# STM32H523 register map
File version: 1.3
CPU: CM33 r0p0, little endian, MPU, FPU, 4 interrupt priority bits
Registers are 32-bit, read-write, reset 0x0 unless marked. A register's access mark holds for its fields unless they carry their own. Offsets are from the block's base; [hi:lo] are bit positions; {n}, {i} and the like mark numbered series.

## TAMP — TAMP register block
Base 0x44007C00
Same registers: TAMP_S 0x54007C00
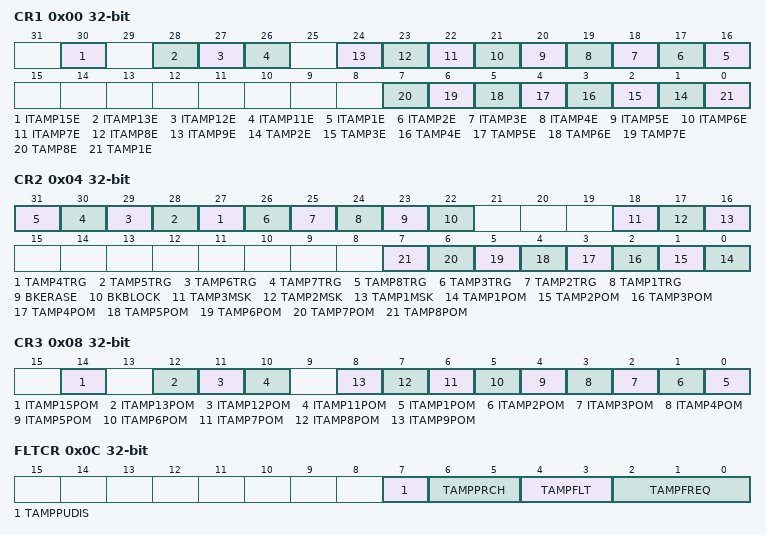
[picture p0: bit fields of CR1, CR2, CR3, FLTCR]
0x00 CR1 — TAMP control register 1
  [30] ITAMP15E — Internal tamper 15 enable
  [28] ITAMP13E — Internal tamper 13 enable
  [27] ITAMP12E — Internal tamper 12 enable
  [26] ITAMP11E — Internal tamper 11 enable
  [n+15] ITAMP{n}E (n=1..9) — Internal tamper {n} enable
  [n-1] TAMP{n}E (n=2..8) — Tamper detection on TAMP_IN{n} enableless thansup>(1)less than/sup>
  [0] TAMP1E — Tamper detection on TAMP_IN1 enable
0x04 CR2 — TAMP control register 2
  [n+23] TAMP{n}TRG (n=4..8) — Active level for tamper {n} input (active mode disabled)
  [26] TAMP3TRG — Active level for tamper 3 input
  [25] TAMP2TRG — Active level for tamper 2 input
  [24] TAMP1TRG — Active level for tamper 1 input
  [23] BKERASE wo — Backup registers and device secretsless thansup>(1)less than/sup> erase
  [22] BKBLOCK — Backup registers and device secretsless thansup>(1)less than/sup> access blocked
  [18] TAMP3MSK — Tamper 3 mask
  [17] TAMP2MSK — Tamper 2 mask
  [16] TAMP1MSK — Tamper 1 mask
  [n-1] TAMP{n}POM (n=1..8) — Tamper {n} potential mode
0x08 CR3 — TAMP control register 3
  [14] ITAMP15POM — Internal tamper 15 potential mode
  [12] ITAMP13POM — Internal tamper 13 potential mode
  [11] ITAMP12POM — Internal tamper 12 potential mode
  [10] ITAMP11POM — Internal tamper 11 potential mode
  [n-1] ITAMP{n}POM (n=1..9) — Internal tamper {n} potential mode
0x0C FLTCR — TAMP filter control register
  [7] TAMPPUDIS — TAMP_INx pull-up disable
  [6:5] TAMPPRCH — TAMP_INx precharge duration
  [4:3] TAMPFLT — TAMP_INx filter count
  [2:0] TAMPFREQ — Tamper sampling frequency
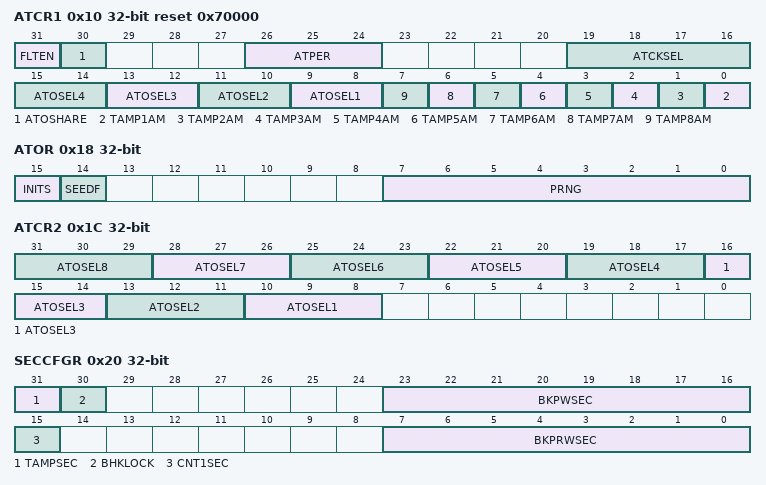
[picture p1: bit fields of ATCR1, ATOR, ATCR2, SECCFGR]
0x10 ATCR1 reset 0x70000 — TAMP active tamper control register 1
  [31] FLTEN — Active tamper filter enable
  [30] ATOSHARE — Active tamper output sharing
  [26:24] ATPER — Active tamper output change period
  [19:16] ATCKSEL — Active tamper RTC asynchronous prescaler clock selection
  [2n+7:2n+6] ATOSEL{n} (n=1..4) — Active tamper shared output {n} selection
  [n-1] TAMP{n}AM (n=1..8) — Tamper {n} active mode
0x14 ATSEEDR wo — TAMP active tamper seed register
  [31:0] SEED — Pseudo-random generator seed value
0x18 ATOR ro — TAMP active tamper output register
  [15] INITS — Active tamper initialization status
  [14] SEEDF — Seed running flag
  [7:0] PRNG — Pseudo-random generator value
0x1C ATCR2 — TAMP active tamper control register 2
  [3n+7:3n+5] ATOSEL{n} (n=1..8) — Active tamper shared output {n} selection
0x20 SECCFGR — TAMP secure configuration register
  [31] TAMPSEC — Tamper protection (excluding monotonic counters and backup registers)
  [30] BHKLOCK — Boot hardware key lock
  [23:16] BKPWSEC — Backup registers write protection offset
  [15] CNT1SEC — Monotonic counter 1 secure protection
  [7:0] BKPRWSEC — Backup registers read/write protection offset
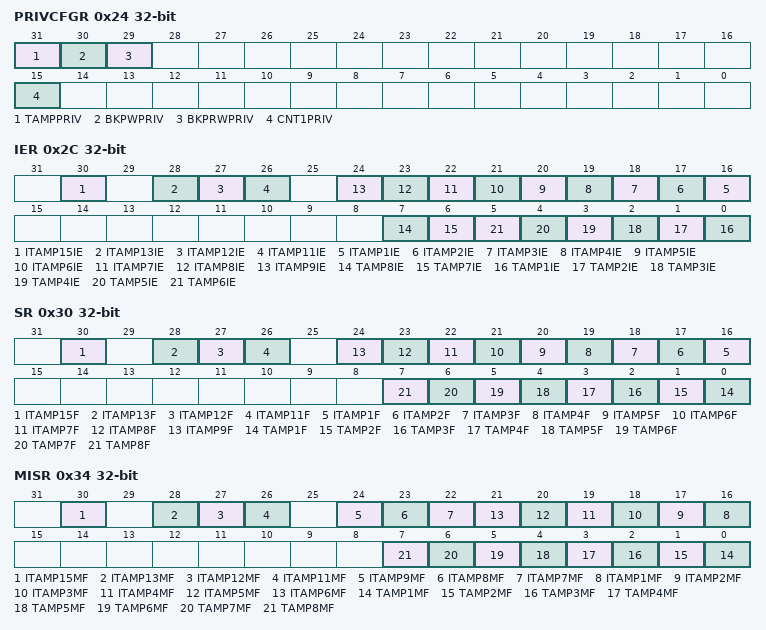
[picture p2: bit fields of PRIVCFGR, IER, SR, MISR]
0x24 PRIVCFGR — TAMP privilege configuration register
  [31] TAMPPRIV — Tamper privilege protection (excluding backup registers)
  [30] BKPWPRIV — Backup registers zone 2 privilege protection
  [29] BKPRWPRIV — Backup registers zone 1 privilege protection
  [15] CNT1PRIV — Monotonic counter 1 privilege protection
0x2C IER — TAMP interrupt enable register
  [30] ITAMP15IE — Internal tamper 15 interrupt enable
  [28] ITAMP13IE — Internal tamper 13 interrupt enable
  [27] ITAMP12IE — Internal tamper 12 interrupt enable
  [26] ITAMP11IE — Internal tamper 11 interrupt enable
  [n+15] ITAMP{n}IE (n=1..9) — Internal tamper {n} interrupt enable
  [7] TAMP8IE — Tamper 8 interrupt enable
  [6] TAMP7IE — Tamper 7interrupt enable
  [n-1] TAMP{n}IE (n=1..6) — Tamper {n} interrupt enable
0x30 SR — TAMP status register
  [30] ITAMP15F — Internal tamper 15 flag
  [28] ITAMP13F ro — Internal tamper 13 flag
  [27] ITAMP12F ro — Internal tamper 12 flag
  [26] ITAMP11F ro — Internal tamper 11 flag
  [n+15] ITAMP{n}F ro (n=1..9) — Internal tamper {n} flag
  [n-1] TAMP{n}F ro (n=1..8) — TAMP{n} detection flag
0x34 MISR ro — TAMP nonsecure masked interrupt status register
  [30] ITAMP15MF — internal tamper 15 nonsecure interrupt masked flag
  [28] ITAMP13MF — internal tamper 13 nonsecure interrupt masked flag
  [27] ITAMP12MF — internal tamper 12 nonsecure interrupt masked flag
  [26] ITAMP11MF — internal tamper 11 nonsecure interrupt masked flag
  [24] ITAMP9MF — internal tamper 9 nonsecure interrupt masked flag
  [23] ITAMP8MF — Internal tamper 8 nonsecure interrupt masked flag
  [22] ITAMP7MF — Internal tamper 7 tamper nonsecure interrupt masked flag
  [n+15] ITAMP{n}MF (n=1..6) — Internal tamper {n} nonsecure interrupt masked flag
  [n-1] TAMP{n}MF (n=1..8) — TAMP{n} nonsecure interrupt masked flag
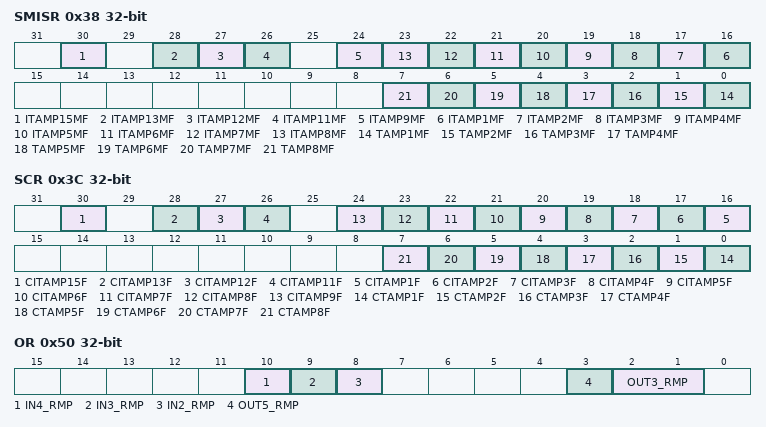
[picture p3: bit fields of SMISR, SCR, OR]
0x38 SMISR ro — TAMP secure masked interrupt status register
  [30] ITAMP15MF — internal tamper 15 secure interrupt masked flag
  [28] ITAMP13MF — internal tamper 13 secure interrupt masked flag
  [27] ITAMP12MF — internal tamper 12 secure interrupt masked flag
  [26] ITAMP11MF — internal tamper 11 secure interrupt masked flag
  [24] ITAMP9MF — internal tamper 9 secure interrupt masked flag
  [n+15] ITAMP{n}MF (n=1..8) — Internal tamper {n} secure interrupt masked flag
  [n-1] TAMP{n}MF (n=1..8) — TAMP{n} secure interrupt masked flag
0x3C SCR wo — TAMP status clear register
  [30] CITAMP15F — Clear ITAMP15 detection flag
  [28] CITAMP13F — Clear ITAMP13 detection flag
  [27] CITAMP12F — Clear ITAMP12 detection flag
  [26] CITAMP11F — Clear ITAMP11 detection flag
  [n+15] CITAMP{n}F (n=1..9) — Clear ITAMP{n} detection flag
  [n-1] CTAMP{n}F (n=1..8) — Clear TAMP{n} detection flag
0x40 COUNT1R ro — TAMP monotonic counter 1 register
  [31:0] COUNT — This register is read-only only and is incremented by one when a write access is done to this register.
0x50 OR — TAMP option register
  [10] IN4_RMP — TAMP_IN4 mapping
  [9] IN3_RMP — TAMP_IN3 mapping
  [8] IN2_RMP — TAMP_IN2 mapping
  [3] OUT5_RMP — TAMP_OUT5 mapping
  [2:1] OUT3_RMP — TAMP_OUT3 mapping
0x54 RPCFGR — TAMP resources protection configuration register
  [0] RPCFG0 — Configurable resource 0 protection
{0x100+4i} BKP{i}R (i=0..31) — TAMP backup {i} register
  [31:0] BKP — The application can write or read data to and from these registers.
